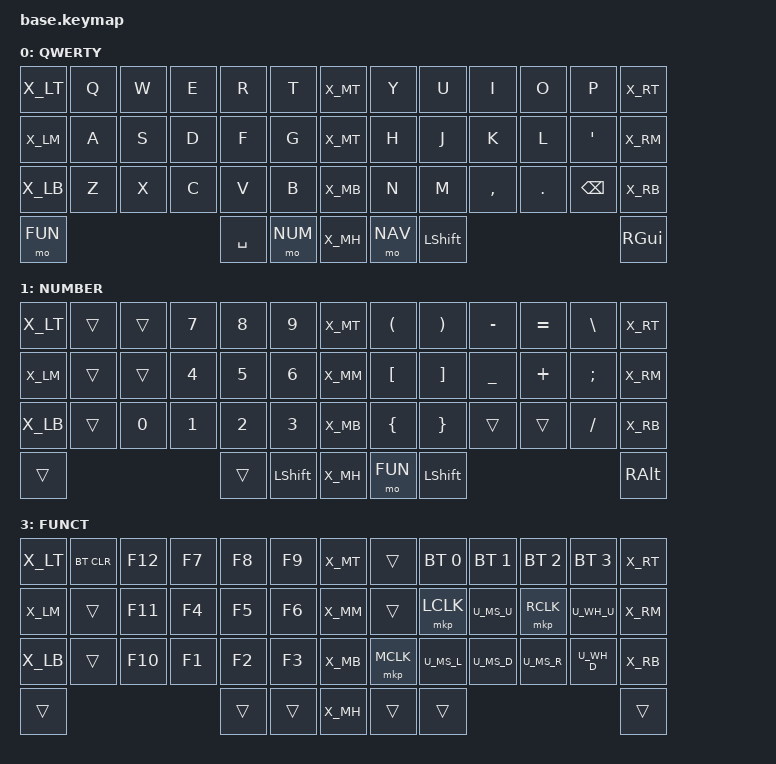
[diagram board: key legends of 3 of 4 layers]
#include <behaviors.dtsi>
#include <behaviors/num_word.dtsi> // requires auto-layer module
#include <dt-bindings/zmk/keys.h>
#if CONFIG_WIRELESS
    #include <dt-bindings/zmk/bt.h>
    #define _BT_SEL_KEYS_ &bt BT_SEL 0 &bt BT_SEL 1 &bt BT_SEL 2 &bt BT_SEL 3 &bt BT_CLR
#else
    #define _BT_SEL_KEYS_ &trans &trans &trans &trans &trans
#endif

#include "zmk-helpers/helper.h"

#define DEF 0
#define NUM 1
#define NAV 2
#define FUN 3

#include "combos.dtsi"  // requires layer aliases
#include "mouse.dtsi"
#include "extra_keys.h"

#define XXX &none
#define ___ &trans

/* Global settings

/* Homerow mods */

#define KEYS_L LT0 LT1 LT2 LT3 LT4 LM0 LM1 LM2 LM3 LM4 LB0 LB1 LB2 LB3 LB4  // left hand
#define KEYS_R RT0 RT1 RT2 RT3 RT4 RM0 RM1 RM2 RM3 RM4 RB0 RB1 RB2 RB3 RB4  // right hand
#define THUMBS LH2 LH1 LH0 RH0 RH1 RH2                                      // thumbs


/* Keymap */

ZMK_LAYER(QWERTY,
//╭──────╮ ╭─────────────┬─────────────┬─────────────┬─────────────┬─────────────╮ ╭──────╮ ╭─────────────┬─────────────┬─────────────┬─────────────┬─────────────╮ ╭──────╮
    X_LT     &kp Q         &kp W         &kp E         &kp R         &kp T           X_MT     &kp Y         &kp U         &kp I         &kp O         &kp P           X_RT
//├──────┤ ├─────────────┼─────────────┼─────────────┼─────────────┼─────────────┤ ├──────┤ ├─────────────┼─────────────┼─────────────┼─────────────┼─────────────┤ ├──────┤
    X_LM     &kp A         &kp S         &kp D         &kp F         &kp G           X_MT     &kp H         &kp J         &kp K         &kp L         &kp SQT         X_RM
//├──────┤ ├─────────────┼─────────────┼─────────────┼─────────────┼─────────────┤ ├──────┤ ├─────────────┼─────────────┼─────────────┼─────────────┼─────────────┤ ├──────┤
    X_LB     &kp Z         &kp X         &kp C         &kp V         &kp B           X_MB     &kp N         &kp M         &kp COMMA     &kp DOT       &kp BSPC        X_RB
//├──────┤ ╰─────────────┼─────────────┴─────────────┼─────────────┼─────────────┤ ├──────┤ ├─────────────┼─────────────┼─────────────┴───────────────────────────╯ ├──────┤
    &mo FUN                                           &kp SPACE     &mo NUM         X_MH     &mo NAV       &kp LSHFT                                                &kp RGUI
//╰──────╯                                           ╰─────────────┴─────────────╯ ╰──────╯ ╰─────────────┴─────────────╯                                           ╰──────╯
)

ZMK_LAYER(NUMBER,
//╭──────╮ ╭─────────────┬─────────────┬─────────────┬─────────────┬─────────────╮ ╭──────╮ ╭─────────────┬─────────────┬─────────────┬─────────────┬─────────────╮ ╭──────╮
    X_LT     ___           ___           &kp N7        &kp N8        &kp N9          X_MT     &kp LPAR      &kp RPAR      &kp MINUS     &kp EQUAL     &kp BSLH        X_RT
//├──────┤ ├─────────────┼─────────────┼─────────────┼─────────────┼─────────────┤ ├──────┤ ├─────────────┼─────────────┼─────────────┼─────────────┼─────────────┤ ├──────┤
    X_LM     ___           ___           &kp N4        &kp N5        &kp N6          X_MM     &kp LBKT      &kp RBKT      &kp UNDER     &kp PLUS      &kp SEMI        X_RM
//├──────┤ ├─────────────┼─────────────┼─────────────┼─────────────┼─────────────┤ ├──────┤ ├─────────────┼─────────────┼─────────────┼─────────────┼─────────────┤ ├──────┤
    X_LB     ___           &kp N0        &kp N1        &kp N2        &kp N3          X_MB     &kp LBRC      &kp RBRC      ___            ___          &kp FSLH        X_RB
//├──────┤ ╰─────────────┼─────────────┴─────────────┼─────────────┼─────────────┤ ├──────┤ ├─────────────┼─────────────┼─────────────┴───────────────────────────╯ ├──────┤
    ___                                                ___           &kp LSHFT       X_MH     &mo FUN       &kp LSHFT                                                 &kp RALT
//╰──────╯                                           ╰─────────────┴─────────────╯ ╰──────╯ ╰─────────────┴─────────────╯                                           ╰──────╯
)

ZMK_LAYER(NAVIGT,
//╭──────╮ ╭─────────────┬─────────────┬─────────────┬─────────────┬─────────────╮ ╭──────╮ ╭─────────────┬─────────────┬─────────────┬─────────────┬─────────────╮ ╭──────╮
    X_LT     &kp ESC       &kp GRAVE     &kp N7        &kp N8        &kp N9          X_MT     &kp LC(C)     &kp LC(V)     &kp INS       &kp HOME      &kp PG_UP       X_RT
//├──────┤ ├─────────────┼─────────────┼─────────────┼─────────────┼─────────────┤ ├──────┤ ├─────────────┼─────────────┼─────────────┼─────────────┼─────────────┤ ├──────┤
    X_LM     ___           &kp LS(LG(S)) &kp N4        &kp N5        &kp N6          X_MM     &kp C_VOL_DN  &kp C_VOL_UP  &kp UP        &kp END       &kp PG_DN       X_RM
//├──────┤ ├─────────────┼─────────────┼─────────────┼─────────────┼─────────────┤ ├──────┤ ├─────────────┼─────────────┼─────────────┼─────────────┼─────────────┤ ├──────┤
    X_LB     ___           &kp N0        &kp N1        &kp N2        &kp N3          X_MB     &kp CAPS      &kp LEFT      &kp DOWN      &kp RIGHT     &kp DEL         X_RB
//├──────┤ ╰─────────────┼─────────────┴─────────────┼─────────────┼─────────────┤ ├──────┤ ├─────────────┼─────────────┼─────────────┴───────────────────────────╯ ├──────┤
    &kp LCTRL		                                   &kp SPACE     ___             X_MH     ___           &kp LSHFT                                                 &kp RALT              ___
//╰──────╯                                           ╰─────────────┴─────────────╯ ╰──────╯ ╰─────────────┴─────────────╯                                           ╰──────╯
)

ZMK_LAYER(FUNCT,
//╭──────╮ ╭─────────────┬─────────────┬─────────────┬─────────────┬─────────────╮ ╭──────╮ ╭─────────────┬─────────────┬─────────────┬─────────────┬─────────────╮ ╭──────╮
    X_LT     &bt BT_CLR    &kp F12       &kp F7        &kp F8        &kp F9          X_MT     ___           &bt BT_SEL 0  &bt BT_SEL 1  &bt BT_SEL 2  &bt BT_SEL 3    X_RT
//├──────┤ ├─────────────┼─────────────┼─────────────┼─────────────┼─────────────┤ ├──────┤ ├─────────────┼─────────────┼─────────────┼─────────────┼─────────────┤ ├──────┤
    X_LM     ___           &kp F11       &kp F4        &kp F5        &kp F6          X_MM     ___           &mkp LCLK     U_MS_U        &mkp RCLK     U_WH_U          X_RM
//├──────┤ ├─────────────┼─────────────┼─────────────┼─────────────┼─────────────┤ ├──────┤ ├─────────────┼─────────────┼─────────────┼─────────────┼─────────────┤ ├──────┤
    X_LB     ___           &kp F10       &kp F1        &kp F2        &kp F3          X_MB     &mkp MCLK     U_MS_L        U_MS_D        U_MS_R        U_WH_D          X_RB
//├──────┤ ╰─────────────┼─────────────┴─────────────┼─────────────┼─────────────┤ ├──────┤ ├─────────────┼─────────────┼─────────────┴───────────────────────────╯ ├──────┤
    ___                                                ___           ___             X_MH     ___           ___                                                       ___
//╰──────╯                                           ╰─────────────┴─────────────╯ ╰──────╯ ╰─────────────┴─────────────╯                                           ╰──────╯
)

/* vim: set ft=c tw=174: */
